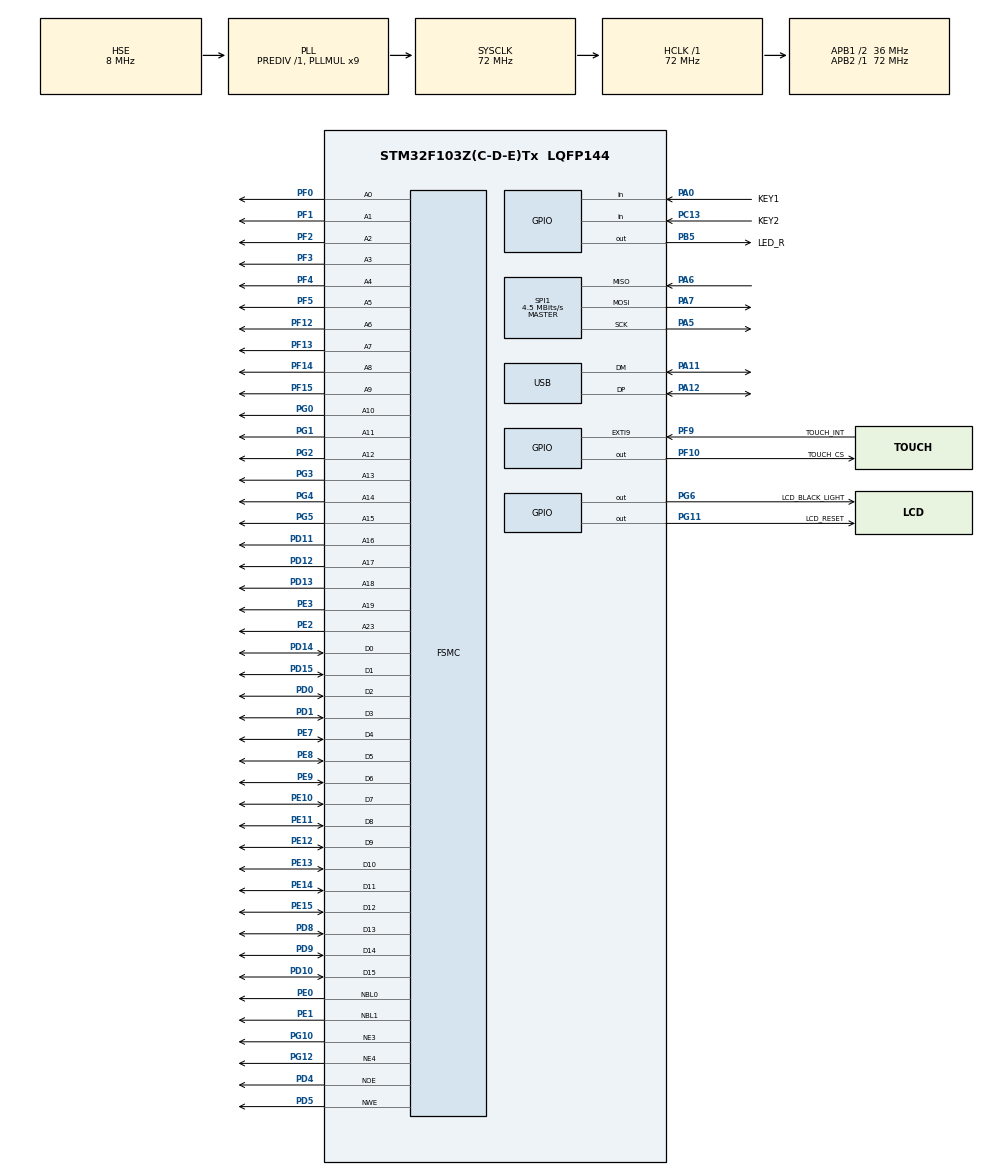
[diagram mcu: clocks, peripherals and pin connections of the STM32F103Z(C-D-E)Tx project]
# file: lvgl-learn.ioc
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FREERTOS.Tasks01=defaultTask,24,128,StartDefaultTask,Default,NULL,Dynamic,NULL,NULL
FREERTOS.configTOTAL_HEAP_SIZE=10240
FSMC.AddressSetupTime3=0
FSMC.AddressSetupTime4=0
FSMC.DataSetupTime3=2
FSMC.DataSetupTime4=2
FSMC.WriteOperation3=FSMC_WRITE_OPERATION_ENABLE
Mcu.Family=STM32F1
Mcu.Name=STM32F103Z(C-D-E)Tx
Mcu.Package=LQFP144
NVIC.PriorityGroup=NVIC_PRIORITYGROUP_4
NVIC.TIM3_IRQn=true\:15\:0\:false\:false\:true\:false\:false\:true\:true
NVIC.TimeBase=TIM3_IRQn
NVIC.TimeBaseIP=TIM3
NVIC.USB_LP_CAN1_RX0_IRQn=true\:5\:0\:false\:false\:true\:true\:false\:true\:true
OSC_IN.Mode=HSE-External-Oscillator
OSC_IN.Signal=RCC_OSC_IN
OSC_OUT.Mode=HSE-External-Oscillator
OSC_OUT.Signal=RCC_OSC_OUT
PA0-WKUP.GPIO_Label=KEY1
PA0-WKUP.Signal=GPIO_Input
PA11.Mode=Device
PA11.Signal=USB_DM
PA12.Mode=Device
PA12.Signal=USB_DP
PA13.Mode=Trace_Asynchronous_SW
PA13.Signal=SYS_JTMS-SWDIO
PA14.Mode=Trace_Asynchronous_SW
PA14.Signal=SYS_JTCK-SWCLK
PA5.Mode=Full_Duplex_Master
PA5.Signal=SPI1_SCK
PA6.Mode=Full_Duplex_Master
PA6.Signal=SPI1_MISO
PA7.Mode=Full_Duplex_Master
PA7.Signal=SPI1_MOSI
PB3.Mode=Trace_Asynchronous_SW
PB3.Signal=SYS_JTDO-TRACESWO
PB5.GPIO_Label=LED_R
PB5.GPIO_Speed=GPIO_SPEED_FREQ_LOW
PB5.Signal=GPIO_Output
PC13-TAMPER-RTC.GPIO_Label=KEY2
PC13-TAMPER-RTC.Signal=GPIO_Input
PC14-OSC32_IN.Mode=LSE-External-Oscillator
PC14-OSC32_IN.Signal=RCC_OSC32_IN
PC15-OSC32_OUT.Mode=LSE-External-Oscillator
PC15-OSC32_OUT.Signal=RCC_OSC32_OUT
PD0.Signal=FSMC_D2_DA2
PD1.Signal=FSMC_D3_DA3
PD10.Signal=FSMC_D15_DA15
PD11.Signal=FSMC_A16_CLE
PD12.Signal=FSMC_A17_ALE
PD13.Signal=FSMC_A18
PD14.Signal=FSMC_D0_DA0
PD15.Signal=FSMC_D1_DA1
PD4.Signal=FSMC_NOE
PD5.Signal=FSMC_NWE
PD8.Signal=FSMC_D13_DA13
PD9.Signal=FSMC_D14_DA14
PE0.Signal=FSMC_NBL0
PE1.Signal=FSMC_NBL1
PE10.Signal=FSMC_D7_DA7
PE11.Signal=FSMC_D8_DA8
PE12.Signal=FSMC_D9_DA9
PE13.Signal=FSMC_D10_DA10
PE14.Signal=FSMC_D11_DA11
PE15.Signal=FSMC_D12_DA12
PE2.Signal=FSMC_A23
PE3.Signal=FSMC_A19
PE7.Signal=FSMC_D4_DA4
PE8.Signal=FSMC_D5_DA5
PE9.Signal=FSMC_D6_DA6
PF0.Signal=FSMC_A0
PF1.Signal=FSMC_A1
PF10.GPIO_Label=TOUCH_CS
PF10.Signal=GPIO_Output
PF12.Signal=FSMC_A6
PF13.Signal=FSMC_A7
PF14.Signal=FSMC_A8
PF15.Signal=FSMC_A9
PF2.Signal=FSMC_A2
PF3.Signal=FSMC_A3
PF4.Signal=FSMC_A4
PF5.Signal=FSMC_A5
PF9.GPIO_Label=TOUCH_INT
PF9.Signal=GPXTI9
PG0.Signal=FSMC_A10
PG1.Signal=FSMC_A11
PG10.Mode=NorPsramChipSelect3_3
PG10.Signal=FSMC_NE3
PG11.GPIO_Label=LCD_RESET
PG11.Signal=GPIO_Output
PG12.Mode=NorPsramChipSelect4_4
PG12.Signal=FSMC_NE4
PG2.Signal=FSMC_A12
PG3.Signal=FSMC_A13
PG4.Signal=FSMC_A14
PG5.Signal=FSMC_A15
PG6.GPIO_Label=LCD_BLACK_LIGHT
PG6.Signal=GPIO_Output
ProjectManager.HeapSize=0x200
ProjectManager.StackSize=0x400
ProjectManager.TargetToolchain=Makefile
RCC.AHBFreq_Value=72000000
RCC.APB1CLKDivider=RCC_HCLK_DIV2
RCC.APB1Freq_Value=36000000
RCC.APB1TimFreq_Value=72000000
RCC.APB2Freq_Value=72000000
RCC.APB2TimFreq_Value=72000000
RCC.HCLKFreq_Value=72000000
RCC.PLLMUL=RCC_PLL_MUL9
RCC.SYSCLKFreq_VALUE=72000000
RCC.SYSCLKSource=RCC_SYSCLKSOURCE_PLLCLK
RCC.USBFreq_Value=48000000
RCC.USBPrescaler=RCC_USBCLKSOURCE_PLL_DIV1_5
SH.FSMC_A0.0=FSMC_A0,20b-a3
SH.FSMC_A1.0=FSMC_A1,20b-a3
SH.FSMC_A10.0=FSMC_A10,20b-a3
SH.FSMC_A11.0=FSMC_A11,20b-a3
SH.FSMC_A12.0=FSMC_A12,20b-a3
SH.FSMC_A13.0=FSMC_A13,20b-a3
SH.FSMC_A14.0=FSMC_A14,20b-a3
SH.FSMC_A15.0=FSMC_A15,20b-a3
SH.FSMC_A16_CLE.0=FSMC_A16,20b-a3
SH.FSMC_A17_ALE.0=FSMC_A17,20b-a3
SH.FSMC_A18.0=FSMC_A18,20b-a3
SH.FSMC_A19.0=FSMC_A19,20b-a3
SH.FSMC_A2.0=FSMC_A2,20b-a3
SH.FSMC_A23.0=FSMC_A23,A23_4
SH.FSMC_A3.0=FSMC_A3,20b-a3
SH.FSMC_A4.0=FSMC_A4,20b-a3
SH.FSMC_A5.0=FSMC_A5,20b-a3
SH.FSMC_A6.0=FSMC_A6,20b-a3
SH.FSMC_A7.0=FSMC_A7,20b-a3
SH.FSMC_A8.0=FSMC_A8,20b-a3
SH.FSMC_A9.0=FSMC_A9,20b-a3
SH.FSMC_D0_DA0.0=FSMC_D0,16b-d4
SH.FSMC_D0_DA0.1=FSMC_D0,16b-d3
SH.FSMC_D10_DA10.0=FSMC_D10,16b-d4
SH.FSMC_D10_DA10.1=FSMC_D10,16b-d3
SH.FSMC_D11_DA11.0=FSMC_D11,16b-d4
SH.FSMC_D11_DA11.1=FSMC_D11,16b-d3
SH.FSMC_D12_DA12.0=FSMC_D12,16b-d4
SH.FSMC_D12_DA12.1=FSMC_D12,16b-d3
SH.FSMC_D13_DA13.0=FSMC_D13,16b-d4
SH.FSMC_D13_DA13.1=FSMC_D13,16b-d3
SH.FSMC_D14_DA14.0=FSMC_D14,16b-d4
SH.FSMC_D14_DA14.1=FSMC_D14,16b-d3
SH.FSMC_D15_DA15.0=FSMC_D15,16b-d4
SH.FSMC_D15_DA15.1=FSMC_D15,16b-d3
SH.FSMC_D1_DA1.0=FSMC_D1,16b-d4
SH.FSMC_D1_DA1.1=FSMC_D1,16b-d3
SH.FSMC_D2_DA2.0=FSMC_D2,16b-d4
SH.FSMC_D2_DA2.1=FSMC_D2,16b-d3
SH.FSMC_D3_DA3.0=FSMC_D3,16b-d4
SH.FSMC_D3_DA3.1=FSMC_D3,16b-d3
SH.FSMC_D4_DA4.0=FSMC_D4,16b-d4
SH.FSMC_D4_DA4.1=FSMC_D4,16b-d3
SH.FSMC_D5_DA5.0=FSMC_D5,16b-d4
SH.FSMC_D5_DA5.1=FSMC_D5,16b-d3
SH.FSMC_D6_DA6.0=FSMC_D6,16b-d4
SH.FSMC_D6_DA6.1=FSMC_D6,16b-d3
SH.FSMC_D7_DA7.0=FSMC_D7,16b-d4
SH.FSMC_D7_DA7.1=FSMC_D7,16b-d3
SH.FSMC_D8_DA8.0=FSMC_D8,16b-d4
SH.FSMC_D8_DA8.1=FSMC_D8,16b-d3
SH.FSMC_D9_DA9.0=FSMC_D9,16b-d4
SH.FSMC_D9_DA9.1=FSMC_D9,16b-d3
SH.FSMC_NBL0.0=FSMC_NBL0,2ByteEnable3
SH.FSMC_NBL1.0=FSMC_NBL1,2ByteEnable3
SH.FSMC_NOE.0=FSMC_NOE,Lcd4
SH.FSMC_NOE.1=FSMC_NOE,Sram3
SH.FSMC_NWE.0=FSMC_NWE,Lcd4
SH.FSMC_NWE.1=FSMC_NWE,Sram3
SPI1.BaudRatePrescaler=SPI_BAUDRATEPRESCALER_16
SPI1.CalculateBaudRate=4.5 MBits/s
SPI1.Direction=SPI_DIRECTION_2LINES
SPI1.Mode=SPI_MODE_MASTER
SPI1.VirtualType=VM_MASTER
USB_DEVICE.CLASS_NAME_FS=MSC
USB_DEVICE.VirtualMode=Msc
USB_DEVICE.VirtualModeFS=Msc_FS
VP_FATFS_VS_Generic.Mode=User_defined
VP_FREERTOS_VS_CMSIS_V2.Mode=CMSIS_V2
VP_SYS_VS_tim3.Mode=TIM3
VP_USB_DEVICE_VS_USB_DEVICE_MSC_FS.Mode=MSC_FS
board=custom

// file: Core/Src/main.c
/* USER CODE BEGIN Header */
/**
  ******************************************************************************
  * @file           : main.c
  * @brief          : Main program body
  ******************************************************************************
  * @attention
  *
  * Copyright (c) 2026 STMicroelectronics.
  * All rights reserved.
  *
  * This software is licensed under terms that can be found in the LICENSE file
  * in the root directory of this software component.
  * If no LICENSE file comes with this software, it is provided AS-IS.
  *
  ******************************************************************************
  */
/* USER CODE END Header */
#include "main.h"
#include "cmsis_os.h"
#include "fatfs.h"
#include "usb_device.h"

/* USER CODE BEGIN Includes */
#include "lcd.h"
#include "FreeRTOS.h"
#include "gui.h"

/* USER CODE END Includes */

SPI_HandleTypeDef hspi1;

SRAM_HandleTypeDef hsram3;
SRAM_HandleTypeDef hsram4;

/* Definitions for defaultTask */
osThreadId_t defaultTaskHandle;
const osThreadAttr_t defaultTask_attributes = {
  .name = "defaultTask",
  .stack_size = 128 * 4,
  .priority = (osPriority_t) osPriorityNormal,
};
/* USER CODE BEGIN PV */
osThreadId_t lvgl_ui_taskHandle;
const osThreadAttr_t LVGLUITask_attributes = {
  .name = "LVGLUITask",
  .stack_size = 1024 * 4,
  .priority = (osPriority_t) osPriorityNormal,
};

/* USER CODE END PV */

void SystemClock_Config(void);
static void MX_GPIO_Init(void);
static void MX_FSMC_Init(void);
static void MX_SPI1_Init(void);
void StartDefaultTask(void *argument);

int main(void)
{

  /* MCU Configuration--------------------------------------------------------*/

  /* Reset of all peripherals, Initializes the Flash interface and the Systick. */
  HAL_Init();

  /* Configure the system clock */
  SystemClock_Config();

  /* Initialize all configured peripherals */
  MX_GPIO_Init();
  MX_FATFS_Init();
  MX_FSMC_Init();
  MX_SPI1_Init();

  /* Init scheduler */
  osKernelInitialize();

  /* Create the thread(s) */
  /* creation of defaultTask */
  defaultTaskHandle = osThreadNew(StartDefaultTask, NULL, &defaultTask_attributes);

  /* USER CODE BEGIN RTOS_THREADS */
  /* add threads, ... */
  lvgl_ui_taskHandle = osThreadNew(StartGUITask, NULL, &LVGLUITask_attributes);
  /* USER CODE END RTOS_THREADS */

  /* Start scheduler */
  osKernelStart();

  /* We should never get here as control is now taken by the scheduler */

  /* Infinite loop */
  while (1)
  {

  }
}

void SystemClock_Config(void)
{
  RCC_OscInitTypeDef RCC_OscInitStruct = {0};
  RCC_ClkInitTypeDef RCC_ClkInitStruct = {0};
  RCC_PeriphCLKInitTypeDef PeriphClkInit = {0};

  /** Initializes the RCC Oscillators according to the specified parameters
  * in the RCC_OscInitTypeDef structure.
  */
  RCC_OscInitStruct.OscillatorType = RCC_OSCILLATORTYPE_HSE;
  RCC_OscInitStruct.HSEState = RCC_HSE_ON;
  RCC_OscInitStruct.HSEPredivValue = RCC_HSE_PREDIV_DIV1;
  RCC_OscInitStruct.HSIState = RCC_HSI_ON;
  RCC_OscInitStruct.PLL.PLLState = RCC_PLL_ON;
  RCC_OscInitStruct.PLL.PLLSource = RCC_PLLSOURCE_HSE;
  RCC_OscInitStruct.PLL.PLLMUL = RCC_PLL_MUL9;
  if (HAL_RCC_OscConfig(&RCC_OscInitStruct) != HAL_OK)
  {
    Error_Handler();
  }

  /** Initializes the CPU, AHB and APB buses clocks
  */
  RCC_ClkInitStruct.ClockType = RCC_CLOCKTYPE_HCLK|RCC_CLOCKTYPE_SYSCLK
                              |RCC_CLOCKTYPE_PCLK1|RCC_CLOCKTYPE_PCLK2;
  RCC_ClkInitStruct.SYSCLKSource = RCC_SYSCLKSOURCE_PLLCLK;
  RCC_ClkInitStruct.AHBCLKDivider = RCC_SYSCLK_DIV1;
  RCC_ClkInitStruct.APB1CLKDivider = RCC_HCLK_DIV2;
  RCC_ClkInitStruct.APB2CLKDivider = RCC_HCLK_DIV1;

  if (HAL_RCC_ClockConfig(&RCC_ClkInitStruct, FLASH_LATENCY_2) != HAL_OK)
  {
    Error_Handler();
  }
  PeriphClkInit.PeriphClockSelection = RCC_PERIPHCLK_USB;
  PeriphClkInit.UsbClockSelection = RCC_USBCLKSOURCE_PLL_DIV1_5;
  if (HAL_RCCEx_PeriphCLKConfig(&PeriphClkInit) != HAL_OK)
  {
    Error_Handler();
  }
}

static void MX_SPI1_Init(void)
{

  /* SPI1 parameter configuration*/
  hspi1.Instance = SPI1;
  hspi1.Init.Mode = SPI_MODE_MASTER;
  hspi1.Init.Direction = SPI_DIRECTION_2LINES;
  hspi1.Init.DataSize = SPI_DATASIZE_8BIT;
  hspi1.Init.CLKPolarity = SPI_POLARITY_LOW;
  hspi1.Init.CLKPhase = SPI_PHASE_1EDGE;
  hspi1.Init.NSS = SPI_NSS_SOFT;
  hspi1.Init.BaudRatePrescaler = SPI_BAUDRATEPRESCALER_16;
  hspi1.Init.FirstBit = SPI_FIRSTBIT_MSB;
  hspi1.Init.TIMode = SPI_TIMODE_DISABLE;
  hspi1.Init.CRCCalculation = SPI_CRCCALCULATION_DISABLE;
  hspi1.Init.CRCPolynomial = 10;
  if (HAL_SPI_Init(&hspi1) != HAL_OK)
  {
    Error_Handler();
  }

}

static void MX_GPIO_Init(void)
{
  GPIO_InitTypeDef GPIO_InitStruct = {0};

  /* GPIO Ports Clock Enable */
  __HAL_RCC_GPIOE_CLK_ENABLE();
  __HAL_RCC_GPIOC_CLK_ENABLE();
  __HAL_RCC_GPIOF_CLK_ENABLE();
  __HAL_RCC_GPIOA_CLK_ENABLE();
  __HAL_RCC_GPIOG_CLK_ENABLE();
  __HAL_RCC_GPIOD_CLK_ENABLE();
  __HAL_RCC_GPIOB_CLK_ENABLE();

  /*Configure GPIO pin Output Level */
  HAL_GPIO_WritePin(TOUCH_CS_GPIO_Port, TOUCH_CS_Pin, GPIO_PIN_RESET);

  /*Configure GPIO pin Output Level */
  HAL_GPIO_WritePin(GPIOG, LCD_BLACK_LIGHT_Pin|LCD_RESET_Pin, GPIO_PIN_RESET);

  /*Configure GPIO pin Output Level */
  HAL_GPIO_WritePin(LED_R_GPIO_Port, LED_R_Pin, GPIO_PIN_RESET);

  /*Configure GPIO pin : KEY2_Pin */
  GPIO_InitStruct.Pin = KEY2_Pin;
  GPIO_InitStruct.Mode = GPIO_MODE_INPUT;
  GPIO_InitStruct.Pull = GPIO_NOPULL;
  HAL_GPIO_Init(KEY2_GPIO_Port, &GPIO_InitStruct);

  /*Configure GPIO pin : TOUCH_INT_Pin */
  GPIO_InitStruct.Pin = TOUCH_INT_Pin;
  GPIO_InitStruct.Mode = GPIO_MODE_IT_RISING;
  GPIO_InitStruct.Pull = GPIO_NOPULL;
  HAL_GPIO_Init(TOUCH_INT_GPIO_Port, &GPIO_InitStruct);

  /*Configure GPIO pin : TOUCH_CS_Pin */
  GPIO_InitStruct.Pin = TOUCH_CS_Pin;
  GPIO_InitStruct.Mode = GPIO_MODE_OUTPUT_PP;
  GPIO_InitStruct.Pull = GPIO_NOPULL;
  GPIO_InitStruct.Speed = GPIO_SPEED_FREQ_LOW;
  HAL_GPIO_Init(TOUCH_CS_GPIO_Port, &GPIO_InitStruct);

  /*Configure GPIO pin : KEY1_Pin */
  GPIO_InitStruct.Pin = KEY1_Pin;
  GPIO_InitStruct.Mode = GPIO_MODE_INPUT;
  GPIO_InitStruct.Pull = GPIO_NOPULL;
  HAL_GPIO_Init(KEY1_GPIO_Port, &GPIO_InitStruct);

  /*Configure GPIO pins : LCD_BLACK_LIGHT_Pin LCD_RESET_Pin */
  GPIO_InitStruct.Pin = LCD_BLACK_LIGHT_Pin|LCD_RESET_Pin;
  GPIO_InitStruct.Mode = GPIO_MODE_OUTPUT_PP;
  GPIO_InitStruct.Pull = GPIO_NOPULL;
  GPIO_InitStruct.Speed = GPIO_SPEED_FREQ_LOW;
  HAL_GPIO_Init(GPIOG, &GPIO_InitStruct);

  /*Configure GPIO pin : LED_R_Pin */
  GPIO_InitStruct.Pin = LED_R_Pin;
  GPIO_InitStruct.Mode = GPIO_MODE_OUTPUT_PP;
  GPIO_InitStruct.Pull = GPIO_NOPULL;
  GPIO_InitStruct.Speed = GPIO_SPEED_FREQ_LOW;
  HAL_GPIO_Init(LED_R_GPIO_Port, &GPIO_InitStruct);

  /* USER CODE BEGIN MX_GPIO_Init_2 */
  HAL_GPIO_WritePin(LCD_BLACK_LIGHT_GPIO_Port, LCD_BLACK_LIGHT_Pin, GPIO_PIN_SET);
  /* USER CODE END MX_GPIO_Init_2 */
}

/* FSMC initialization function */
static void MX_FSMC_Init(void)
{

  FSMC_NORSRAM_TimingTypeDef Timing = {0};

  /** Perform the SRAM3 memory initialization sequence
  */
  hsram3.Instance = FSMC_NORSRAM_DEVICE;
  hsram3.Extended = FSMC_NORSRAM_EXTENDED_DEVICE;
  /* hsram3.Init */
  hsram3.Init.NSBank = FSMC_NORSRAM_BANK3;
  hsram3.Init.DataAddressMux = FSMC_DATA_ADDRESS_MUX_DISABLE;
  hsram3.Init.MemoryType = FSMC_MEMORY_TYPE_SRAM;
  hsram3.Init.MemoryDataWidth = FSMC_NORSRAM_MEM_BUS_WIDTH_16;
  hsram3.Init.BurstAccessMode = FSMC_BURST_ACCESS_MODE_DISABLE;
  hsram3.Init.WaitSignalPolarity = FSMC_WAIT_SIGNAL_POLARITY_LOW;
  hsram3.Init.WrapMode = FSMC_WRAP_MODE_DISABLE;
  hsram3.Init.WaitSignalActive = FSMC_WAIT_TIMING_BEFORE_WS;
  hsram3.Init.WriteOperation = FSMC_WRITE_OPERATION_ENABLE;
  hsram3.Init.WaitSignal = FSMC_WAIT_SIGNAL_DISABLE;
  hsram3.Init.ExtendedMode = FSMC_EXTENDED_MODE_DISABLE;
  hsram3.Init.AsynchronousWait = FSMC_ASYNCHRONOUS_WAIT_DISABLE;
  hsram3.Init.WriteBurst = FSMC_WRITE_BURST_DISABLE;
  /* Timing */
  Timing.AddressSetupTime = 0;
  Timing.AddressHoldTime = 15;
  Timing.DataSetupTime = 2;
  Timing.BusTurnAroundDuration = 15;
  Timing.CLKDivision = 16;
  Timing.DataLatency = 17;
  Timing.AccessMode = FSMC_ACCESS_MODE_A;
  /* ExtTiming */

  if (HAL_SRAM_Init(&hsram3, &Timing, NULL) != HAL_OK)
  {
    Error_Handler( );
  }

  /** Perform the SRAM4 memory initialization sequence
  */
  hsram4.Instance = FSMC_NORSRAM_DEVICE;
  hsram4.Extended = FSMC_NORSRAM_EXTENDED_DEVICE;
  /* hsram4.Init */
  hsram4.Init.NSBank = FSMC_NORSRAM_BANK4;
  hsram4.Init.DataAddressMux = FSMC_DATA_ADDRESS_MUX_DISABLE;
  hsram4.Init.MemoryType = FSMC_MEMORY_TYPE_SRAM;
  hsram4.Init.MemoryDataWidth = FSMC_NORSRAM_MEM_BUS_WIDTH_16;
  hsram4.Init.BurstAccessMode = FSMC_BURST_ACCESS_MODE_DISABLE;
  hsram4.Init.WaitSignalPolarity = FSMC_WAIT_SIGNAL_POLARITY_LOW;
  hsram4.Init.WrapMode = FSMC_WRAP_MODE_DISABLE;
  hsram4.Init.WaitSignalActive = FSMC_WAIT_TIMING_BEFORE_WS;
  hsram4.Init.WriteOperation = FSMC_WRITE_OPERATION_ENABLE;
  hsram4.Init.WaitSignal = FSMC_WAIT_SIGNAL_DISABLE;
  hsram4.Init.ExtendedMode = FSMC_EXTENDED_MODE_DISABLE;
  hsram4.Init.AsynchronousWait = FSMC_ASYNCHRONOUS_WAIT_DISABLE;
  hsram4.Init.WriteBurst = FSMC_WRITE_BURST_DISABLE;
  /* Timing */
  Timing.AddressSetupTime = 0;
  Timing.AddressHoldTime = 15;
  Timing.DataSetupTime = 2;
  Timing.BusTurnAroundDuration = 15;
  Timing.CLKDivision = 16;
  Timing.DataLatency = 17;
  Timing.AccessMode = FSMC_ACCESS_MODE_A;
  /* ExtTiming */

  if (HAL_SRAM_Init(&hsram4, &Timing, NULL) != HAL_OK)
  {
    Error_Handler( );
  }

  /** Disconnect NADV
  */

  __HAL_AFIO_FSMCNADV_DISCONNECTED();

}

void StartDefaultTask(void *argument)
{
  /* init code for USB_DEVICE */
  MX_USB_DEVICE_Init();
  /* USER CODE BEGIN 5 */
  /* USER CODE EN D 5 */
  /* Infinite loop */

  for (;;)
  {
    osDelay(pdMS_TO_TICKS(1000));
    HAL_GPIO_TogglePin(LED_R_GPIO_Port, LED_R_Pin);
  }
  /* USER CODE END 5 */
}

void HAL_TIM_PeriodElapsedCallback(TIM_HandleTypeDef *htim)
{
  if (htim->Instance == TIM3)
  {
    HAL_IncTick();
  }
}

void Error_Handler(void)
{
  __disable_irq();
  while (1)
  {
  }
}
